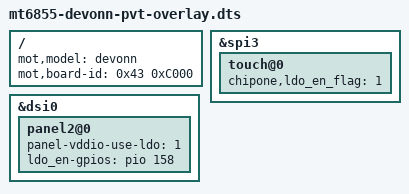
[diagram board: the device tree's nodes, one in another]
/* Copyright (c) 2019, Motorola Mobility Inc. All rights reserved.
 *
 * This program is free software; you can redistribute it and/or modify
 * it under the terms of the GNU General Public License version 2 and
 * only version 2 as published by the Free Software Foundation.
 *
 * This program is distributed in the hope that it will be useful,
 * but WITHOUT ANY WARRANTY; without even the implied warranty of
 * MERCHANTABILITY or FITNESS FOR A PARTICULAR PURPOSE.  See the
 * GNU General Public License for more details.
 */

/dts-v1/;
/plugin/;

#include "mediatek/mt6855-devonn-common-overlay.dtsi"

/* Board match root node */
/ {
	fragment@model {
		target-path = "/";
		__overlay__ {
			mot,model = "devonn";
			mot,board-id = <0x43 0xC000>;
		};
	};
};

/* TOUCH start */

&spi3 {

	touch@0{

		chipone,ldo_en_flag = <1>;
	};
};
/* TOUCH end */
/* DISPLAY start */
&dsi0 {
	panel2@0 {
		panel-vddio-use-ldo = <1>;
		ldo_en-gpios = <&pio 158 0>;
	};
};
/* DISPLAY END */
#include <devonn_pvt/cust.dtsi>
/*End of this file, DO NOT ADD ANYTHING HERE*/
